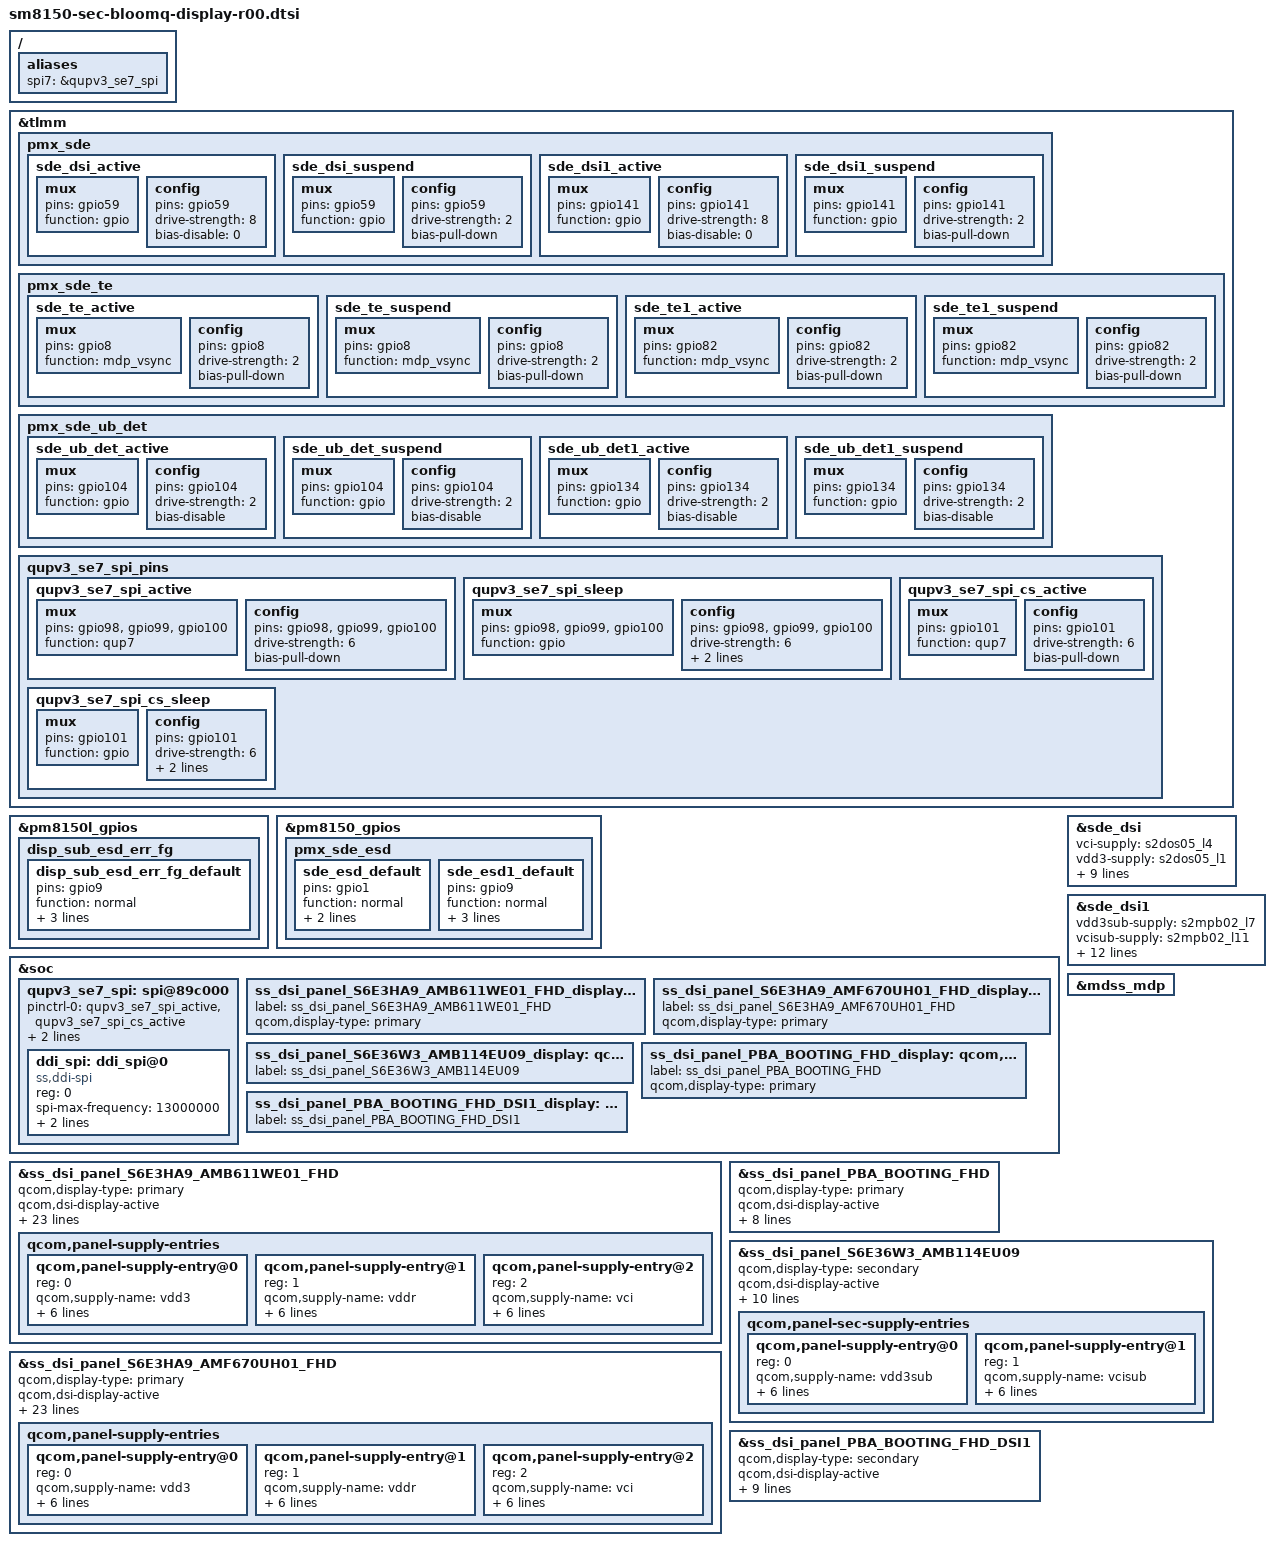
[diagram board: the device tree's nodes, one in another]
/* Copyright (c) 2016-2017, The Linux Foundation. All rights reserved.
 *
 * This program is free software; you can redistribute it and/or modify
 * it under the terms of the GNU General Public License version 2 and
 * only version 2 as published by the Free Software Foundation.
 *
 * This program is distributed in the hope that it will be useful,
 * but WITHOUT ANY WARRANTY; without even the implied warranty of
 * MERCHANTABILITY or FITNESS FOR A PARTICULAR PURPOSE.  See the
 * GNU General Public License for more details.
 */

#include "../../../../../drivers/gpu/drm/msm/samsung/SELF_DISPLAY/self_display_cmd_HA9.dtsi"
#include "../../../../../drivers/gpu/drm/msm/samsung/SELF_DISPLAY/self_display_cmd_HA9_AMF670UH01.dtsi"
#include "../../../../../drivers/gpu/drm/msm/samsung/S6E3HA9_AMB611WE01/dsi_panel_S6E3HA9_AMB611WE01_fhd_octa_cmd.dtsi"
#include "../../../../../drivers/gpu/drm/msm/samsung/S6E3HA9_AMF670UH01/dsi_panel_S6E3HA9_AMF670UH01_fhd_octa_cmd.dtsi"
#include "../../../../../drivers/gpu/drm/msm/samsung/S6E36W3_AMB114EU09/dsi_panel_S6E36W3_AMB114EU09_octa_cmd.dtsi"
#include "../../../../../drivers/gpu/drm/msm/samsung/SELF_DISPLAY/self_display_cmd_6W3.dtsi"
#include "../../../../../drivers/gpu/drm/msm/samsung/PBA_BOOTING/dsi_panel_PBA_BOOTING_fhd_video.dtsi"
#include "../../../../../drivers/gpu/drm/msm/samsung/PBA_BOOTING_DSI1/dsi_panel_PBA_BOOTING_fhd_video_dsi1.dtsi"

/{
	aliases {
		spi7 = &qupv3_se7_spi;
	};
};


&tlmm {
	pmx_sde: pmx_sde {
		sde_dsi_active: sde_dsi_active {
			mux {
				pins = "gpio59";
				function = "gpio";
			};

			config {
				pins = "gpio59";
				drive-strength = <8>;   /* 8 mA */
				bias-disable = <0>;   /* no pull */
			};
		};
		sde_dsi_suspend: sde_dsi_suspend {
			mux {
				pins = "gpio59";
				function = "gpio";
			};

			config {
				pins = "gpio59";
				drive-strength = <2>;   /* 2 mA */
				bias-pull-down;         /* PULL DOWN */
			};
		};
		sde_dsi1_active: sde_dsi1_active {
			mux {
				pins = "gpio141";
				function = "gpio";
			};

			config {
				pins = "gpio141";
				drive-strength = <8>;   /* 8 mA */
				bias-disable = <0>;   /* no pull */
			};
		};
		sde_dsi1_suspend: sde_dsi1_suspend {
			mux {
				pins = "gpio141";
				function = "gpio";
			};

			config {
				pins = "gpio141";
				drive-strength = <2>;   /* 2 mA */
				bias-pull-down;         /* PULL DOWN */
			};
		};
	};
	pmx_sde_te {
		sde_te_active: sde_te_active {
			mux {
				pins = "gpio8";
				function = "mdp_vsync";
			};

			config {
				pins = "gpio8";
				drive-strength = <2>;   /* 2 mA */
				bias-pull-down;         /* PULL DOWN */
			};
		};

		sde_te_suspend: sde_te_suspend {
			mux {
				pins = "gpio8";
				function = "mdp_vsync";
			};

			config {
				pins = "gpio8";
				drive-strength = <2>;   /* 2 mA */
				bias-pull-down;         /* PULL DOWN */
			};
		};
		sde_te1_active: sde_te1_active {
			mux {
				pins = "gpio82";
				function = "mdp_vsync";
			};

			config {
				pins = "gpio82";
				drive-strength = <2>;   /* 2 mA */
				bias-pull-down;         /* PULL DOWN */
			};
		};

		sde_te1_suspend: sde_te1_suspend {
			mux {
				pins = "gpio82";
				function = "mdp_vsync";
			};

			config {
				pins = "gpio82";
				drive-strength = <2>;   /* 2 mA */
				bias-pull-down;         /* PULL DOWN */
			};
		};
	};
	pmx_sde_ub_det {
		sde_ub_det_active: sde_ub_det_active {
			mux {
				pins = "gpio104";
				function = "gpio";
			};

			config {
				pins = "gpio104";
				drive-strength = <2>;   /* 2 mA */
				bias-disable;   /* no pull */
			};
		};

		sde_ub_det_suspend: sde_ub_det_suspend {
			mux {
				pins = "gpio104";
				function = "gpio";
			};

			config {
				pins = "gpio104";
				drive-strength = <2>;   /* 2 mA */
				bias-disable;   /* no pull */
			};
		};

		sde_ub_det1_active: sde_ub_det1_active {
			mux {
				pins = "gpio134";
				function = "gpio";
			};

			config {
				pins = "gpio134";
				drive-strength = <2>;   /* 2 mA */
				bias-disable;   /* no pull */
			};
		};

		sde_ub_det1_suspend: sde_ub_det1_suspend {
			mux {
				pins = "gpio134";
				function = "gpio";
			};

			config {
				pins = "gpio134";
				drive-strength = <2>;   /* 2 mA */
				bias-disable;   /* no pull */
			};
		};
	};

	qupv3_se7_spi_pins: qupv3_se7_spi_pins {
		qupv3_se7_spi_active: qupv3_se7_spi_active {
			mux {
				pins = "gpio98", "gpio99", "gpio100";
				function = "qup7";
			};

			config {
				pins = "gpio98", "gpio99", "gpio100";
				drive-strength = <6>;
				bias-pull-down; /* prevent MISO floating */
			};
		};

		qupv3_se7_spi_sleep: qupv3_se7_spi_sleep {
			mux {
				pins = "gpio98", "gpio99", "gpio100";
				function = "gpio";
			};

			config {
				pins = "gpio98", "gpio99", "gpio100";
				drive-strength = <6>;
				bias-pull-down;
				input-enable;
			};
		};

		qupv3_se7_spi_cs_active: qupv3_se7_spi_cs_active {
			mux {
				pins = "gpio101";
				function = "qup7";
			};

			config {
				pins = "gpio101";
				drive-strength = <6>;
				bias-pull-down; /* prevent MISO floating */
			};
		};

		qupv3_se7_spi_cs_sleep: qupv3_se7_spi_cs_sleep {
			mux {
				pins = "gpio101";
				function = "gpio";
			};

			config {
				pins = "gpio101";
				drive-strength = <6>;
				bias-disable;           /* NO PULL */
				input-enable;
			};
		};
	};
};

&pm8150l_gpios {
		disp_sub_esd_err_fg {
				disp_sub_esd_err_fg_default: disp_sub_esd_err_fg_default {
					pins = "gpio9";
					function = "normal";
					input-enable;
					bias-disable;
					power-source = <1>;
				};
		};
};
&pm8150_gpios {
		pmx_sde_esd {
				sde_esd_default: sde_esd_default {
					pins = "gpio1";
					function = "normal";
					input-enable;
					bias-disable;
				};
				sde_esd1_default: sde_esd1_default {
					pins = "gpio9";
					function = "normal";
					input-enable;
					bias-disable;
					power-source = <1>;
				};
		};
};

&soc {
	qupv3_se7_spi: spi@89c000 {
		status = "ok";

		pinctrl-0 = <&qupv3_se7_spi_active &qupv3_se7_spi_cs_active>;
		pinctrl-1 = <&qupv3_se7_spi_sleep &qupv3_se7_spi_cs_sleep>;

		ddi_spi:ddi_spi@0  {	// LCD_SPI
			compatible = "ss,ddi-spi";
			reg = <0>;
			spi-max-frequency = <13000000>;
			spi-mode = <0>;
			spi-bpw = <8>;
		};
	};
};

&soc {
	/* B1 3040 panel Rev00*/
	ss_dsi_panel_S6E3HA9_AMB611WE01_FHD_display: qcom,dsi-display@3 {
		label = "ss_dsi_panel_S6E3HA9_AMB611WE01_FHD";
		qcom,display-type = "primary";
	};

	/* Bloom panel Rev01*/
	ss_dsi_panel_S6E3HA9_AMF670UH01_FHD_display: qcom,dsi-display@5 {
		label = "ss_dsi_panel_S6E3HA9_AMF670UH01_FHD";
		qcom,display-type = "primary";
	};

	/* bloom sub panel */
	ss_dsi_panel_S6E36W3_AMB114EU09_display: qcom,dsi-display@18 {
		label = "ss_dsi_panel_S6E36W3_AMB114EU09";
	};

	/* PBA */
	ss_dsi_panel_PBA_BOOTING_FHD_display: qcom,dsi-display@0 {
		label = "ss_dsi_panel_PBA_BOOTING_FHD";
		qcom,display-type = "primary";
	};

	/* PBA for secondary display (DSI1) */
	ss_dsi_panel_PBA_BOOTING_FHD_DSI1_display: qcom,dsi-display@20 {
		label = "ss_dsi_panel_PBA_BOOTING_FHD_DSI1";
	};
};

/* override display-list / supply for samsung panel */
&sde_dsi {

	vci-supply = <&s2dos05_l4>; /* 3.0V, S2DOS05 LDO4 */
	vdd3-supply = <&s2dos05_l1>; /* 1.8V, S2DOS05 LDO1 */
	vddr-supply = <&s2dos05_buck1>; /* 1.6V, S2DOS05 buck */

	pinctrl-names = "panel_active", "panel_suspend";
	pinctrl-0 = <&sde_dsi_active &sde_te_active &sde_ub_det_active &sde_esd_default>;
	pinctrl-1 = <&sde_dsi_suspend &sde_te_suspend &sde_ub_det_suspend &sde_esd_default>;

	qcom,dsi-display-list =
		<&ss_dsi_panel_S6E3HA9_AMB611WE01_FHD
		&ss_dsi_panel_S6E3HA9_AMF670UH01_FHD
		&ss_dsi_panel_PBA_BOOTING_FHD>;
};


/* override display-list / supply for samsung panel */
&sde_dsi1 {
	vdd3sub-supply = <&s2mpb02_l7>; /* VDD_SUB_DDI_1P8, S2MPB02 VLDO7 */
	vcisub-supply = <&s2mpb02_l11>; /* VDD_SUB_DDI_3P3, S2MPB02 VLDO11 */
	pinctrl-names = "panel_active", "panel_suspend";
	pinctrl-0 = <&sde_dsi1_active &sde_te1_active &sde_ub_det1_active &disp_sub_esd_err_fg_default &sde_esd1_default>;
	pinctrl-1 = <&sde_dsi1_suspend &sde_te1_suspend &sde_ub_det1_suspend &disp_sub_esd_err_fg_default &sde_esd1_default>;

	qcom,platform-te-gpio = <&tlmm 82 0>;

	qcom,dsi-display-list =
		<&ss_dsi_panel_S6E36W3_AMB114EU09
		&ss_dsi_panel_PBA_BOOTING_FHD_DSI1>;
};

&mdss_mdp {
	/* display node, like ss_dsi_panel_S6E3HA6_AMS622MR01_WQHD_display,
	 * will be added by cmdline.
	 * If your board doesn't use cmdline to select display node,
	 * add display node like below.
	 * connectors = <&sde_rscc &sde_wb &sde_dp &ss_dsi_panel_S6E3HA6_AMS622MR01_WQHD_display>;
	 */
};

&ss_dsi_panel_S6E3HA9_AMB611WE01_FHD {
	qcom,display-type = "primary";
	qcom,dsi-display-active;

	qcom,dsi-ctrl-num = <0>;
	qcom,dsi-phy-num = <0>;
	qcom,dsi-select-clocks = "mux_byte_clk0", "mux_pixel_clk0";

	qcom,dsi-panel = <&ss_dsi_panel_S6E3HA9_AMB611WE01_FHD>;

	qcom,platform-reset-gpio = <&tlmm 59 0>;
	qcom,platform-te-gpio = <&tlmm 8 0>;

	/delete-property/ qcom,panel-mode-gpio;

	qcom,panel-supply-entries {
		#address-cells = <1>;
		#size-cells = <0>;

		qcom,panel-supply-entry@0 {
		    reg = <0>;
		    qcom,supply-name = "vdd3";
		    qcom,supply-min-voltage = <1800000>;
		    qcom,supply-max-voltage = <1800000>;
		    qcom,supply-enable-load = <100000>;
		    qcom,supply-disable-load = <100>;
		    qcom,supply-pre-on-sleep = <0>; /* unit is ms*/
		    qcom,supply-post-on-sleep = <0>;
		};

		qcom,panel-supply-entry@1 {
		    reg = <1>;
		    qcom,supply-name = "vddr";
		    qcom,supply-min-voltage = <1700000>;
		    qcom,supply-max-voltage = <1700000>;
		    qcom,supply-enable-load = <100000>;
		    qcom,supply-disable-load = <100>;
		    qcom,supply-pre-on-sleep = <0>; /* unit is ms*/
		    qcom,supply-post-on-sleep = <0>;
		};

		qcom,panel-supply-entry@2 {
		    reg = <2>;
		    qcom,supply-name = "vci";
		    qcom,supply-min-voltage = <3000000>;
		    qcom,supply-max-voltage = <3000000>;
		    qcom,supply-enable-load = <100000>;
		    qcom,supply-disable-load = <100>;
		    qcom,supply-pre-on-sleep = <0>; /* unit is ms*/
		    qcom,supply-post-on-sleep = <10>;
		};
	};
};

&ss_dsi_panel_S6E3HA9_AMB611WE01_FHD {
	samsung,esd-irq-gpio1 = <&pm8150_gpios 1 0>; // DISP_DET
	samsung,delayed-display-on = <1>;

	samsung,ub-con-det = <&tlmm 104 0>; /* Bloom REV01*/

	samsung,lpm-power-control;
	samsung,lpm-power-control-supply-name = "vddr";
	samsung,lpm-power-control-supply-min-voltage = <1500000>;
	samsung,lpm-power-control-supply-max-voltage = <1500000>;
	samsung,lpm-power-control-elvss-name = "s2dos05-elvss";
	samsung,lpm-power-control-elvss-lpm-voltage = <2000>;
	samsung,lpm-power-control-elvss-normal-voltage = <8000>;
};

&ss_dsi_panel_S6E3HA9_AMF670UH01_FHD {
	qcom,display-type = "primary";
	qcom,dsi-display-active;

	qcom,dsi-ctrl-num = <0>;
	qcom,dsi-phy-num = <0>;
	qcom,dsi-select-clocks = "mux_byte_clk0", "mux_pixel_clk0";

	qcom,dsi-panel = <&ss_dsi_panel_S6E3HA9_AMF670UH01_FHD>;

	qcom,platform-reset-gpio = <&tlmm 59 0>;
	qcom,platform-te-gpio = <&tlmm 8 0>;

	/delete-property/ qcom,panel-mode-gpio;

	qcom,panel-supply-entries {
		#address-cells = <1>;
		#size-cells = <0>;

		qcom,panel-supply-entry@0 {
		    reg = <0>;
		    qcom,supply-name = "vdd3";
		    qcom,supply-min-voltage = <1800000>;
		    qcom,supply-max-voltage = <1800000>;
		    qcom,supply-enable-load = <100000>;
		    qcom,supply-disable-load = <100>;
		    qcom,supply-pre-on-sleep = <0>; /* unit is ms*/
		    qcom,supply-post-on-sleep = <0>;
		};

		qcom,panel-supply-entry@1 {
		    reg = <1>;
		    qcom,supply-name = "vddr";
		    qcom,supply-min-voltage = <1700000>;
		    qcom,supply-max-voltage = <1700000>;
		    qcom,supply-enable-load = <100000>;
		    qcom,supply-disable-load = <100>;
		    qcom,supply-pre-on-sleep = <0>; /* unit is ms*/
		    qcom,supply-post-on-sleep = <0>;
		};

		qcom,panel-supply-entry@2 {
		    reg = <2>;
		    qcom,supply-name = "vci";
		    qcom,supply-min-voltage = <3000000>;
		    qcom,supply-max-voltage = <3000000>;
		    qcom,supply-enable-load = <100000>;
		    qcom,supply-disable-load = <100>;
		    qcom,supply-pre-on-sleep = <0>; /* unit is ms*/
		    qcom,supply-post-on-sleep = <10>;
		};
	};
};

&ss_dsi_panel_S6E3HA9_AMF670UH01_FHD {
	samsung,esd-irq-gpio1 = <&pm8150_gpios 1 0>; // DISP_DET
	samsung,delayed-display-on = <1>;

	samsung,ub-con-det = <&tlmm 104 0>; /* Bloom REV01*/

	samsung,lpm-power-control;
	samsung,lpm-power-control-supply-name = "vddr";
	samsung,lpm-power-control-supply-min-voltage = <1500000>;
	samsung,lpm-power-control-supply-max-voltage = <1500000>;
	samsung,lpm-power-control-elvss-name = "s2dos05-elvss";
	samsung,lpm-power-control-elvss-lpm-voltage = <2000>;
	samsung,lpm-power-control-elvss-normal-voltage = <8000>;
};

&ss_dsi_panel_PBA_BOOTING_FHD {
	qcom,display-type = "primary";
	qcom,dsi-display-active;

	qcom,dsi-ctrl-num = <0>;
	qcom,dsi-phy-num = <0>;
	qcom,dsi-select-clocks = "mux_byte_clk0", "mux_pixel_clk0";

	qcom,dsi-panel = <&ss_dsi_panel_PBA_BOOTING_FHD>;

	qcom,platform-reset-gpio = <&tlmm 59 0>;
	qcom,platform-te-gpio = <&tlmm 8 0>;
	/* In pba booting mode, SS disables continuous splash mode.
	 * But QC recommended to enable splash mode as default..
	 * In case of splash enabled, it should not touch has_src_split  setitng..
	 * Refer to case 03756419.
	 */
	samsung,enable_splash_pba; /* enable continuous spalsh on PBA mode.. */
};

&ss_dsi_panel_S6E36W3_AMB114EU09 {
	qcom,display-type = "secondary";
	qcom,dsi-display-active;

	qcom,dsi-ctrl-num = <1>;
	qcom,dsi-phy-num = <1>;
	qcom,dsi-select-clocks = "mux_byte_clk1", "mux_pixel_clk1";

	qcom,dsi-panel = <&ss_dsi_panel_S6E36W3_AMB114EU09>;

	qcom,platform-sec-reset-gpio = <&tlmm 141 0>;
	qcom,platform-te-source = <1>;

	/delete-property/ qcom,panel-mode-gpio;

	qcom,panel-sec-supply-entries {
		#address-cells = <1>;
		#size-cells = <0>;

		qcom,panel-supply-entry@0 {
		    reg = <0>;
		    qcom,supply-name = "vdd3sub";
		    qcom,supply-min-voltage = <1800000>;
		    qcom,supply-max-voltage = <1800000>;
		    qcom,supply-enable-load = <100000>;
		    qcom,supply-disable-load = <100>;
		    qcom,supply-pre-on-sleep = <0>; /* unit is ms*/
		    qcom,supply-post-on-sleep = <0>;
		};
		qcom,panel-supply-entry@1 {
		    reg = <1>;
		    qcom,supply-name = "vcisub";
		    qcom,supply-min-voltage = <3300000>;
		    qcom,supply-max-voltage = <3300000>;
		    qcom,supply-enable-load = <100000>;
		    qcom,supply-disable-load = <100>;
		    qcom,supply-pre-on-sleep = <0>; /* unit is ms*/
		    qcom,supply-post-on-sleep = <10>;
		};
	};
};
&ss_dsi_panel_S6E36W3_AMB114EU09 {
	samsung,esd-irq-gpio1 = <&pm8150_gpios 9 0>; //SUB_DISP_DET
	//samsung,esd-irq-gpio1 = <&pm8150l_gpios 9 0>; //SUB_DISP_ERR_FG
	samsung,ub-con-det = <&tlmm 134 0>; /* Bloom REV01*/
};

&ss_dsi_panel_PBA_BOOTING_FHD_DSI1 {
	qcom,display-type = "secondary";
	qcom,dsi-display-active;

	qcom,dsi-ctrl-num = <1>;
	qcom,dsi-phy-num = <1>;
	qcom,dsi-select-clocks = "mux_byte_clk1", "mux_pixel_clk1";

	qcom,dsi-panel = <&ss_dsi_panel_PBA_BOOTING_FHD_DSI1>;

	qcom,platform-sec-reset-gpio = <&tlmm 141 0>;
	qcom,platform-te-source = <1>;
	/* In pba booting mode, SS disables continuous splash mode.
	 * But QC recommended to enable splash mode as default..
	 * In case of splash enabled, it should not touch has_src_split  setitng..
	 * Refer to case 03756419.
	 */
	samsung,enable_splash_pba; /* enable continuous spalsh on PBA mode.. */
};
